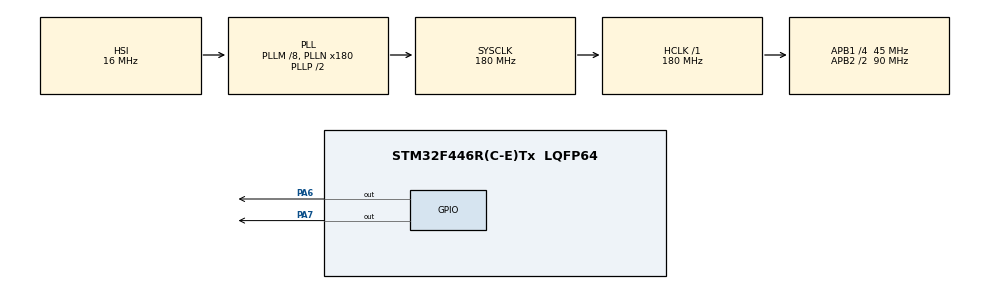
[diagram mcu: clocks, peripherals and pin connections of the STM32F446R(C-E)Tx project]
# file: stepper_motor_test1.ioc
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Mcu.Family=STM32F4
Mcu.Name=STM32F446R(C-E)Tx
Mcu.Package=LQFP64
NVIC.PriorityGroup=NVIC_PRIORITYGROUP_4
NVIC.TIM1_BRK_TIM9_IRQn=true\:0\:0\:false\:false\:true\:true\:true\:true
NVIC.TIM4_IRQn=true\:0\:0\:false\:false\:true\:true\:true\:true
PA13.Mode=Serial_Wire
PA13.Signal=SYS_JTMS-SWDIO
PA14.Mode=Serial_Wire
PA14.Signal=SYS_JTCK-SWCLK
PA6.Signal=GPIO_Output
PA7.Signal=GPIO_Output
PH0-OSC_IN.Mode=HSE-External-Oscillator
PH0-OSC_IN.Signal=RCC_OSC_IN
PH1-OSC_OUT.Mode=HSE-External-Oscillator
PH1-OSC_OUT.Signal=RCC_OSC_OUT
ProjectManager.HeapSize=0x200
ProjectManager.StackSize=0x400
ProjectManager.TargetToolchain=STM32CubeIDE
RCC.AHBFreq_Value=180000000
RCC.APB1CLKDivider=RCC_HCLK_DIV4
RCC.APB1Freq_Value=45000000
RCC.APB1TimFreq_Value=90000000
RCC.APB2CLKDivider=RCC_HCLK_DIV2
RCC.APB2Freq_Value=90000000
RCC.APB2TimFreq_Value=180000000
RCC.CortexFreq_Value=180000000
RCC.HCLKFreq_Value=180000000
RCC.HSE_VALUE=25000000
RCC.PLLM=8
RCC.PLLN=180
RCC.SYSCLKFreq_VALUE=180000000
RCC.SYSCLKSource=RCC_SYSCLKSOURCE_PLLCLK
RCC.USBFreq_Value=180000000
RCC.VCOOutputFreq_Value=360000000
TIM4.AutoReloadPreload=TIM_AUTORELOAD_PRELOAD_ENABLE
TIM4.Period=9999
TIM4.Prescaler=89
TIM9.AutoReloadPreload=TIM_AUTORELOAD_PRELOAD_ENABLE
TIM9.Period=0xffff-1
TIM9.Prescaler=179
VP_TIM4_VS_ClockSourceINT.Mode=Internal
VP_TIM9_VS_ClockSourceINT.Mode=Internal
board=custom

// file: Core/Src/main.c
/* USER CODE BEGIN Header */
/**
  ******************************************************************************
  * @file           : main.c
  * @brief          : Main program body
  ******************************************************************************
  * @attention
  *
  * Copyright (c) 2023 STMicroelectronics.
  * All rights reserved.
  *
  * This software is licensed under terms that can be found in the LICENSE file
  * in the root directory of this software component.
  * If no LICENSE file comes with this software, it is provided AS-IS.
  *
  ******************************************************************************
  */
/* USER CODE END Header */
#include "main.h"
#include "tim.h"
#include "gpio.h"

/* USER CODE BEGIN Includes */
#include "Accel_stepper.h"
/*#include <stdio.h>
#include "mpu6050.h"*/
/* USER CODE END Includes */

/* USER CODE BEGIN PTD */
Acceleration_t Stepper1;

/* USER CODE END PTD */

/* USER CODE BEGIN PV */
int stepDelay = 500; // 1000us more delay means less speed
signed int set_theta1=800*19;
int counter=0;
/* USER CODE END PV */

void SystemClock_Config(void);
/* USER CODE BEGIN PFP */
void microDelay (uint16_t delay)
{

  __HAL_TIM_SET_COUNTER(&htim9, 0);
  while (__HAL_TIM_GET_COUNTER(&htim9) < delay);
  //HAL_TIM_Base_Stop_IT(&htim9);
}
void stepper_Motor (int steps, uint8_t direction, uint16_t delay)
{
  int x;
  if (direction == 0)
  {
    HAL_GPIO_WritePin(GPIOA, GPIOA_PIN_7, GPIO_PIN_SET);
  }
  else
  {
    HAL_GPIO_WritePin(DIR_PORT, DIR_PIN, GPIO_PIN_RESET);
  }
  for(x=0; x<steps; x=x+1)
  {
    HAL_GPIO_WritePin(STEP_PORT, STEP_PIN, GPIO_PIN_SET);
    microDelay(delay);
    HAL_GPIO_WritePin(STEP_PORT, STEP_PIN, GPIO_PIN_RESET);
    microDelay(delay);
  }
}

void HAL_TIM_PeriodElapsedCallback(TIM_HandleTypeDef *htim);
void stepper_set_rpm (uint16_t rpm);
//void microDelay (uint16_t delay);
/* USER CODE END PFP */

/* USER CODE BEGIN 0 */

int stepDelay = 500; // 1000us more delay means less speed
signed int set_theta1=800*19;
void microDelay (uint16_t delay)
{

  __HAL_TIM_SET_COUNTER(&htim9, 0);
  while (__HAL_TIM_GET_COUNTER(&htim9) < delay);
  //HAL_TIM_Base_Stop_IT(&htim9);
}

/* USER CODE END 0 */

int main(void)
{

  /* MCU Configuration--------------------------------------------------------*/

  /* Reset of all peripherals, Initializes the Flash interface and the Systick. */
  HAL_Init();

  /* Configure the system clock */
  SystemClock_Config();

  /* Initialize all configured peripherals */
  MX_GPIO_Init();
  MX_TIM9_Init();
  MX_TIM4_Init();
  /* USER CODE BEGIN 2 */
  //HAL_TIM_Base_Start_IT(&htim9);
  //HAL_TIM_Base_Start_IT(&htim4);
  Accel_Stepper_SetPin(&Stepper1, GPIOA, GPIO_PIN_6, GPIOA, GPIO_PIN_7);
  Accel_Stepper_SetTimer(&Stepper1, &htim4);
  /* USER CODE END 2 */

  /* Infinite loop */
  while (1)
  {

    /* USER CODE BEGIN 3 */
	  // when use in in main() : while (1)

	  	  /*printf("The value of counter is : %d \r\n", counter);
	  	  counter++;
	  	  fflush(stdout);
	  	  HAL_Delay(10);*/

	  	  //int x;
	      /*HAL_GPIO_WritePin(GPIOA,  GPIO_PIN_7, GPIO_PIN_SET);
	      for(x=0; x<3800; x=x+1)
	      {
	    	HAL_GPIO_TogglePin(GPIOA, GPIO_PIN_6);
	        microDelay(stepDelay);
	      }
	      HAL_Delay(1000);*/
	  	  if(Stepper1.run_status == 0){
	  		  Accel_Stepper_Move(&Stepper1, set_theta1, 1000, 1000, 500);
	  		  set_theta1 = 0;//reset steps to 0 (prevent re-run after done)
	  	  }
	      /*HAL_GPIO_WritePin(GPIOA,  GPIO_PIN_7, GPIO_PIN_SET);
	      for(x=0; x<7600; x=x+1)
	      {
	        HAL_GPIO_WritePin(GPIOA, GPIO_PIN_6, GPIO_PIN_SET);
	        microDelay(stepDelay);
	        HAL_GPIO_WritePin(GPIOA, GPIO_PIN_6, GPIO_PIN_RESET);
	        microDelay(stepDelay);
	      }
	      HAL_Delay(1000);*/

  }
  /* USER CODE END 3 */
}

void SystemClock_Config(void)
{
  RCC_OscInitTypeDef RCC_OscInitStruct = {0};
  RCC_ClkInitTypeDef RCC_ClkInitStruct = {0};

  /** Configure the main internal regulator output voltage
  */
  __HAL_RCC_PWR_CLK_ENABLE();
  __HAL_PWR_VOLTAGESCALING_CONFIG(PWR_REGULATOR_VOLTAGE_SCALE1);

  /** Initializes the RCC Oscillators according to the specified parameters
  * in the RCC_OscInitTypeDef structure.
  */
  RCC_OscInitStruct.OscillatorType = RCC_OSCILLATORTYPE_HSI;
  RCC_OscInitStruct.HSIState = RCC_HSI_ON;
  RCC_OscInitStruct.HSICalibrationValue = RCC_HSICALIBRATION_DEFAULT;
  RCC_OscInitStruct.PLL.PLLState = RCC_PLL_ON;
  RCC_OscInitStruct.PLL.PLLSource = RCC_PLLSOURCE_HSI;
  RCC_OscInitStruct.PLL.PLLM = 8;
  RCC_OscInitStruct.PLL.PLLN = 180;
  RCC_OscInitStruct.PLL.PLLP = RCC_PLLP_DIV2;
  RCC_OscInitStruct.PLL.PLLQ = 2;
  RCC_OscInitStruct.PLL.PLLR = 2;
  if (HAL_RCC_OscConfig(&RCC_OscInitStruct) != HAL_OK)
  {
    Error_Handler();
  }

  /** Activate the Over-Drive mode
  */
  if (HAL_PWREx_EnableOverDrive() != HAL_OK)
  {
    Error_Handler();
  }

  /** Initializes the CPU, AHB and APB buses clocks
  */
  RCC_ClkInitStruct.ClockType = RCC_CLOCKTYPE_HCLK|RCC_CLOCKTYPE_SYSCLK
                              |RCC_CLOCKTYPE_PCLK1|RCC_CLOCKTYPE_PCLK2;
  RCC_ClkInitStruct.SYSCLKSource = RCC_SYSCLKSOURCE_PLLCLK;
  RCC_ClkInitStruct.AHBCLKDivider = RCC_SYSCLK_DIV1;
  RCC_ClkInitStruct.APB1CLKDivider = RCC_HCLK_DIV4;
  RCC_ClkInitStruct.APB2CLKDivider = RCC_HCLK_DIV2;

  if (HAL_RCC_ClockConfig(&RCC_ClkInitStruct, FLASH_LATENCY_5) != HAL_OK)
  {
    Error_Handler();
  }
}

/* USER CODE BEGIN 4 */
void HAL_TIM_PeriodElapsedCallback(TIM_HandleTypeDef *htim){

	  if(htim->Instance == TIM4){//stepper1
		  Accel_Stepper_TIMIT_Handler(&Stepper1);

	  }
}

/* USER CODE END 4 */

void Error_Handler(void)
{
  __disable_irq();
  while (1)
  {
  }
}
